# EFR32FG25B222F1920IM56 register map
Vendor: Silicon Labs; Series: EFR32; File version: B
Registers are 32-bit, read-write, reset 0x0 unless marked. A register's access mark holds for its fields unless they carry their own. Offsets are from the block's base; [hi:lo] are bit positions; {n}, {i} and the like mark numbered series.

## FSRCO_NS — FSRCO_NS Registers
Base 0x50018000
Same registers: FSRCO_S 0x40018000
0x00 IPVERSION ro

## GPCRC_NS — GPCRC_NS Registers
Base 0x50088000
Same registers: GPCRC_S 0x40088000
0x00 IPVERSION ro
  [31:0] IPVERSION — IP Version ID
0x04 EN
  [0] EN — CRC Enable
    0=DISABLE (Disable CRC function. Reordering functions are still available. Only BITREVERSE and BYTEREVERSE bits are configurable in this mode.); 1=ENABLE (Writes to INPUTDATA registers will result in CRC operations.)
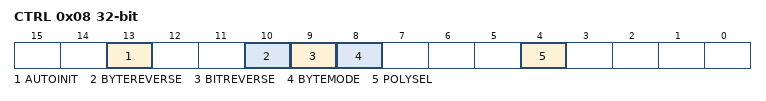
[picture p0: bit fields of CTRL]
0x08 CTRL
  [13] AUTOINIT — Auto Init Enable
  [10] BYTEREVERSE — Byte Reverse Mode
    0=NORMAL (No reverse: B3, B2, B1, B0); 1=REVERSED (Reverse byte order. For 32-bit: B0, B1, B2, B3; For 16-bit: 0, 0, B0, B1)
  [9] BITREVERSE — Byte-level Bit Reverse Enable
    0=NORMAL (No reverse); 1=REVERSED (Reverse bit order in each byte)
  [8] BYTEMODE — Byte Mode Enable
  [4] POLYSEL — Polynomial Select
    0=CRC32 (CRC-32 (0x04C11DB7) polynomial selected); 1=CRC16 (16-bit CRC programmable polynomial selected)
0x0C CMD wo
  [0] INIT — Initialization Enable
0x10 INIT
  [31:0] INIT — CRC Initialization Value
0x14 POLY
  [15:0] POLY — CRC Polynomial Value
0x18 INPUTDATA wo
  [31:0] INPUTDATA — Input Data for 32-bit
0x1C INPUTDATAHWORD wo
  [15:0] INPUTDATAHWORD — Input Data for 16-bit
0x20 INPUTDATABYTE wo
  [7:0] INPUTDATABYTE — Input Data for 8-bit
0x24 DATA ro
  [31:0] DATA — CRC Data Register
0x28 DATAREV ro
  [31:0] DATAREV — Data Reverse Value
0x2C DATABYTEREV ro
  [31:0] DATABYTEREV — Data Byte Reverse Value

## HFRCO0_NS — HFRCO0_NS Registers
Base 0x50010000
Same registers: HFRCO0_S 0x40010000, HFRCOEM23_S 0x4A000000, HFRCOEM23_NS 0x5A000000
0x00 IPVERSION ro reset 0x2
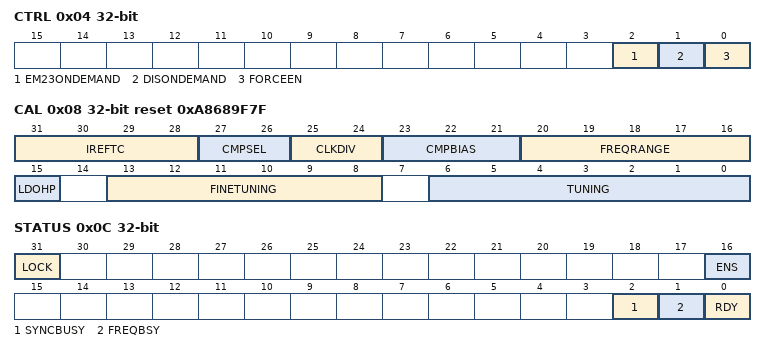
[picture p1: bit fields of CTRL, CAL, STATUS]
0x04 CTRL
  [2] EM23ONDEMAND
  [1] DISONDEMAND — Disable On-demand
  [0] FORCEEN — Force Enable
0x08 CAL reset 0xA8689F7F
  [31:28] IREFTC — Tempco Trim on Comparator Current
  [27:26] CMPSEL — Comparator Load Select
  [25:24] CLKDIV — Locally Divide HFRCO Clock Output
    0=DIV1 (Divide by 1.); 1=DIV2 (Divide by 2.); 2=DIV4 (Divide by 4.)
  [23:21] CMPBIAS — Comparator Bias Current
  [20:16] FREQRANGE — Frequency Range
  [15] LDOHP — LDO High Power Mode
  [13:8] FINETUNING — Fine Tuning Value
  [6:0] TUNING — Tuning Value
0x0C STATUS ro
  [31] LOCK — Lock Status
    0=UNLOCKED (HFRCO is unlocked); 1=LOCKED (HFRCO is locked)
  [16] ENS — Enable Status
  [2] SYNCBUSY — Synchronization Busy
  [1] FREQBSY — Frequency Updating Busy
  [0] RDY — Ready
0x10 IF
  [0] RDY — Ready Interrupt Flag
0x14 IEN
  [0] RDY — RDY Interrupt Enable
0x1C LOCK wo reset 0x8195
  [15:0] LOCKKEY
    0x8195=UNLOCK (Unlock code)

## HOSTMAILBOX_NS — HOSTMAILBOX_NS Registers
Base 0x50098000
Same registers: HOSTMAILBOX_S 0x40098000
{0x0+4i} MSGPTR{i} (i=0..3)
  [31:0] PTR — Pointer
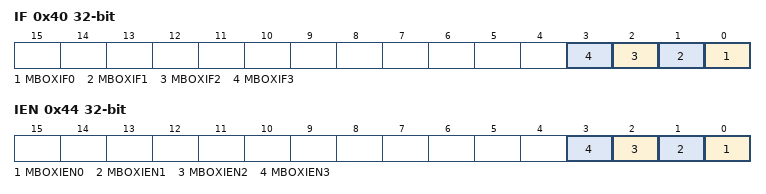
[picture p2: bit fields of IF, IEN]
0x40 IF
  [n] MBOXIF{n} (n=0..3) — Mailbox Interupt Flag
0x44 IEN
  [n] MBOXIEN{n} (n=0..3) — Mailbox Interrupt Enable

## ICACHE0_NS — ICACHE0_NS Registers
Base 0x50034000
Same registers: ICACHE0_S 0x40034000
0x00 IPVERSION ro — The read only IPVERSION field gives the version for this module. There may be minor software changes required for modules with different values of IPVERSION.
  [31:0] IPVERSION — IP version ID
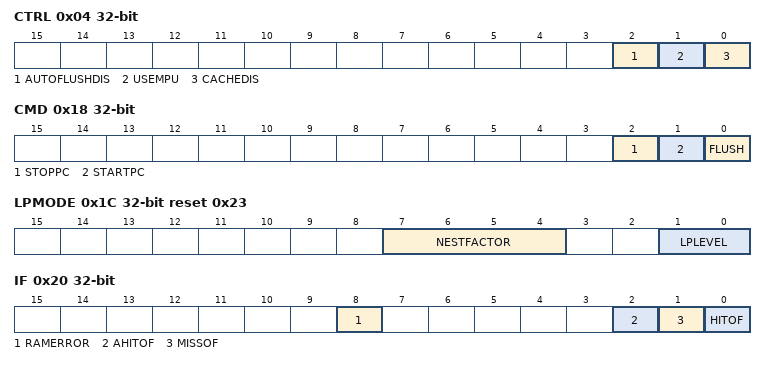
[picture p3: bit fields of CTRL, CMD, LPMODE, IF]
0x04 CTRL
  [2] AUTOFLUSHDIS — Automatic Flushing Disable
  [1] USEMPU
  [0] CACHEDIS — Cache Disable
0x08 PCHITS ro
  [31:0] PCHITS — Performance Counter Hits
0x0C PCMISSES ro
  [31:0] PCMISSES — Performance Counter Misses
0x10 PCAHITS ro
  [31:0] PCAHITS — Performance Counter Advanced Hits
0x14 STATUS ro
  [0] PCRUNNING
0x18 CMD wo
  [2] STOPPC — Stop Performance Counters
  [1] STARTPC — Start Performance Counters
  [0] FLUSH
0x1C LPMODE reset 0x23
  [7:4] NESTFACTOR — Low Power Nest Factor
  [1:0] LPLEVEL — Low Power Level
    0=BASIC (Base instruction cache functionality); 1=ADVANCED (Advanced buffering mode, where the cache uses the fetch pattern to predict highly accessed data and store it in low-energy memory); 3=MINACTIVITY (Minimum activity mode, which allows the cache to minimize activity in logic that it predicts has a low probability being used. This mode can introduce wait-states into the instruction fetch stream when the cache exits one of its low-activity states. The number of wait-states introduced is small, but users running with 0-wait-state memory and wishing to reduce the variability that the cache might introduce with additional wait-states may wish to lower the cache low-power level. Note, this mode includes the advanced buffering mode functionality.)
0x20 IF
  [8] RAMERROR — RAM error Interrupt Flag
  [2] AHITOF — Advanced Hit Overflow Interrupt Flag
  [1] MISSOF — Miss Overflow Interrupt Flag
  [0] HITOF — Hit Overflow Interrupt Flag
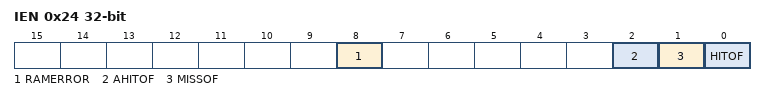
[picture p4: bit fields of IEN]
0x24 IEN
  [8] RAMERROR — RAM error Interrupt Enable
  [2] AHITOF — Advanced Hit Overflow Interrupt Enable
  [1] MISSOF — Miss Overflow Interrupt Enable
  [0] HITOF — Hit Overflow Interrupt Enable
